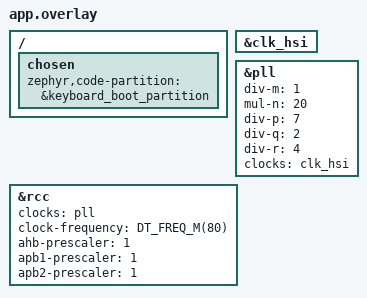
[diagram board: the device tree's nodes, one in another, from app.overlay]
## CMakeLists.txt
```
# SPDX-License-Identifier: Apache-2.0
cmake_minimum_required(VERSION 3.28.0)

set(BOARD_ROOT ${CMAKE_CURRENT_LIST_DIR}/../..)
find_package(Zephyr REQUIRED HINTS $ENV{ZEPHYR_BASE})
project(ef800_keyboard_bootloader)

target_sources(app PRIVATE
	src/main.c
	src/keyboard_boot_handoff.c
	src/keyboard_boot_probe.c
	src/keyboard_boot_flash.c
	${CMAKE_CURRENT_LIST_DIR}/../../shared/ef800_keyboard_boot/ef800_keyboard_boot.c
	${CMAKE_CURRENT_LIST_DIR}/../../shared/ef800_update/ef800_update.c
	${CMAKE_CURRENT_LIST_DIR}/../../shared/ef800_watchdog/ef800_watchdog.c
)

target_include_directories(app PRIVATE
	${CMAKE_CURRENT_LIST_DIR}/../../shared/ef800_keyboard_boot
	${CMAKE_CURRENT_LIST_DIR}/../../shared/ef800_update
	${CMAKE_CURRENT_LIST_DIR}/../../shared/ef800_watchdog
)
```

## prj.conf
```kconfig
# SPDX-License-Identifier: Apache-2.0
CONFIG_IS_BOOTLOADER=y
CONFIG_FLASH=y
CONFIG_FLASH_MAP=y
CONFIG_FLASH_PAGE_LAYOUT=y
CONFIG_GPIO=y
CONFIG_I2C=y
CONFIG_I2C_TARGET=y
CONFIG_HWINFO=y
CONFIG_WATCHDOG=y
# Software-started IWDG: do not enable an option-byte/hardware-started IWDG.
CONFIG_IWDG_STM32_INITIAL_TIMEOUT=10000
CONFIG_USE_DT_CODE_PARTITION=y
CONFIG_LOG=y
CONFIG_LOG_MODE_IMMEDIATE=y
CONFIG_SERIAL=n
CONFIG_CONSOLE=n
CONFIG_UART_CONSOLE=n
CONFIG_MAIN_STACK_SIZE=2048
```

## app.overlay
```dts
/* SPDX-License-Identifier: Apache-2.0 */
/ {
	chosen {
		zephyr,code-partition = &keyboard_boot_partition;
	};
};

&clk_hsi {
	status = "okay";
};

&pll {
	div-m = <1>;
	mul-n = <20>;
	div-p = <7>;
	div-q = <2>;
	div-r = <4>;
	clocks = <&clk_hsi>;
	status = "okay";
};

&rcc {
	clocks = <&pll>;
	clock-frequency = <DT_FREQ_M(80)>;
	ahb-prescaler = <1>;
	apb1-prescaler = <1>;
	apb2-prescaler = <1>;
};
```

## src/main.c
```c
/* SPDX-License-Identifier: Apache-2.0 */
/** @file @brief Validate keyboard images and select application or updater boot. */
#include <stdbool.h>
#include <stdint.h>

#include <zephyr/devicetree.h>
#include <zephyr/drivers/hwinfo.h>
#include <zephyr/kernel.h>
#include <zephyr/logging/log.h>
#include <zephyr/storage/flash_map.h>
#include <zephyr/sys/util.h>

#include "ef800_keyboard_boot.h"
#include "ef800_watchdog.h"
#include "keyboard_boot_handoff.h"
#include "keyboard_boot_flash.h"
#include "keyboard_boot_probe.h"

LOG_MODULE_REGISTER(ef800_keyboard_bootloader, LOG_LEVEL_INF);

#define APP_PARTITION_ID PARTITION_ID(keyboard_app_partition)
#define UPDATER_PARTITION_ID PARTITION_ID(keyboard_updater_partition)

BUILD_ASSERT(PARTITION_OFFSET(keyboard_boot_partition) == 0U);
BUILD_ASSERT(PARTITION_SIZE(keyboard_boot_partition) == 0x8000U);
BUILD_ASSERT(PARTITION_OFFSET(keyboard_app_partition) == 0x8000U);
BUILD_ASSERT(PARTITION_SIZE(keyboard_app_partition) == 0x30000U);
BUILD_ASSERT(PARTITION_OFFSET(keyboard_updater_partition) == 0x38000U);
BUILD_ASSERT(PARTITION_SIZE(keyboard_updater_partition) == 0x8000U);


static FUNC_NORETURN void jump_to_image(uintptr_t address, size_t size)
{
	if (!ef800_keyboard_boot_handoff(address, size)) {
		LOG_ERR("invalid boot target 0x%lx", (unsigned long)address);
		for (;;) {
			k_sleep(K_FOREVER);
		}
	}
	for (;;) {
		k_sleep(K_FOREVER);
	}
}

static FUNC_NORETURN void enter_updater(void)
{
	if (ef800_keyboard_boot_probe_unregister() != 0) {
		LOG_WRN("keyboard boot: I2C target unregister failed");
	}
	if (!ef800_keyboard_boot_updater_valid()) {
		LOG_ERR("keyboard boot: updater image invalid");
		for (;;) {
			(void)ef800_watchdog_feed();
			k_sleep(K_SECONDS(1));
		}
	}
	(void)ef800_watchdog_feed();
	jump_to_image(PARTITION_ADDRESS(keyboard_updater_partition),
		PARTITION_SIZE(keyboard_updater_partition));
}

int main(void)
{
	const struct flash_area *app;
	struct ef800_keyboard_boot_state *state = ef800_keyboard_boot_state_get();
	uint32_t cause = 0U;
	bool watchdog;
	bool recovery_required;
	bool application_is_valid;
	bool gpio_updater_request;
	bool i2c_updater_probe = false;
	int probe_result;

	(void)hwinfo_get_reset_cause(&cause);
	watchdog = (cause & RESET_WATCHDOG) != 0U;
	(void)hwinfo_clear_reset_cause();
	if ((cause & (RESET_POR | RESET_BROWNOUT)) != 0U) {
		ef800_keyboard_boot_state_initialize(state);
	}
	recovery_required = ef800_keyboard_boot_prepare(state, watchdog, cause);

	/* Start or adopt IWDG before the bounded updater-entry window. */
	if (ef800_watchdog_start(10000U) != 0) {
		LOG_ERR("keyboard IWDG could not be started");
	}
	probe_result = ef800_keyboard_boot_probe_gpio(&gpio_updater_request);
	if (probe_result != 0) {
		LOG_WRN("keyboard boot: updater request GPIO unavailable: %d",
			probe_result);
	}
	if (gpio_updater_request) {
		LOG_INF("keyboard boot: PB12 updater request asserted");
		enter_updater();
	}
	if (ef800_keyboard_boot_should_enter_updater(false,
			recovery_required, true)) {
		LOG_WRN("keyboard boot: watchdog recovery limit reached; entering updater");
		enter_updater();
	}
	probe_result = ef800_keyboard_boot_probe_window(&i2c_updater_probe);
	if (probe_result != 0) {
		LOG_ERR("keyboard boot: I2C probe unavailable: %d", probe_result);
	}
	if (ef800_keyboard_boot_should_enter_updater(i2c_updater_probe,
			false, true)) {
		LOG_INF("keyboard boot: updater probe received");
		enter_updater();
	}

	if (flash_area_open(APP_PARTITION_ID, &app) != 0 ||
		!flash_area_device_is_ready(app)) {
		LOG_ERR("keyboard boot: application Flash unavailable; entering updater");
		enter_updater();
	}
	application_is_valid = ef800_keyboard_boot_application_valid(app);
	if (ef800_keyboard_boot_should_enter_updater(false, false,
			application_is_valid)) {
		(void)flash_area_close(app);
		LOG_ERR("keyboard boot: application invalid; entering updater");
		enter_updater();
	}
	(void)flash_area_close(app);
	jump_to_image(PARTITION_ADDRESS(keyboard_app_partition),
		PARTITION_SIZE(keyboard_app_partition));
}
```

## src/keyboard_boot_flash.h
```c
/* SPDX-License-Identifier: Apache-2.0 */

#ifndef EF800_KEYBOARD_BOOT_FLASH_H
#define EF800_KEYBOARD_BOOT_FLASH_H

#include <stdbool.h>

#include <zephyr/storage/flash_map.h>

bool ef800_keyboard_boot_application_valid(const struct flash_area *area);
bool ef800_keyboard_boot_updater_valid(void);

#endif /* EF800_KEYBOARD_BOOT_FLASH_H */
```

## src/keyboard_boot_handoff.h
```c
/* SPDX-License-Identifier: Apache-2.0 */
/** @file
 * @brief Transfer execution to a validated keyboard firmware image.
 */

#ifndef EF800_KEYBOARD_BOOT_HANDOFF_H
#define EF800_KEYBOARD_BOOT_HANDOFF_H

#include <stdbool.h>
#include <stddef.h>
#include <stdint.h>

/** @brief Set the processor state and branch to an image reset vector.
 * @param address Image base address.
 * @param size Image extent used to validate its vector table.
 * @return True if the handoff was attempted; false if image bounds are invalid.
 */
bool ef800_keyboard_boot_handoff(uintptr_t address, size_t size);

#endif /* EF800_KEYBOARD_BOOT_HANDOFF_H */
```

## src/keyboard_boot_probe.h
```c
/* SPDX-License-Identifier: Apache-2.0 */

#ifndef EF800_KEYBOARD_BOOT_PROBE_H
#define EF800_KEYBOARD_BOOT_PROBE_H

#include <stdbool.h>

int ef800_keyboard_boot_probe_gpio(bool *requested);
int ef800_keyboard_boot_probe_window(bool *received);
int ef800_keyboard_boot_probe_unregister(void);

#endif /* EF800_KEYBOARD_BOOT_PROBE_H */
```
